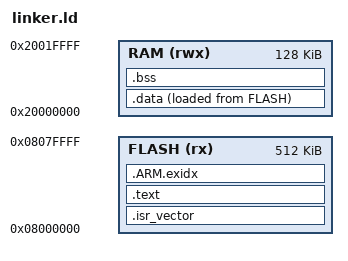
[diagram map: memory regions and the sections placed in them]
ENTRY(Reset_Handler)

MEMORY
{
    FLASH (rx)  : ORIGIN = 0x08000000, LENGTH = 512K
    RAM   (rwx) : ORIGIN = 0x20000000, LENGTH = 128K
}

_estack = ORIGIN(RAM) + LENGTH(RAM);
_stack_size = 4K;

SECTIONS
{
    .isr_vector :
    {
        . = ALIGN(4);
        KEEP(*(.isr_vector))
        . = ALIGN(4);
    } > FLASH

    .text :
    {
        . = ALIGN(4);
        *(.text*)
        *(.rodata*)
        KEEP(*(.init))
        KEEP(*(.fini))
        . = ALIGN(4);
        _etext = .;
    } > FLASH

    .ARM.exidx :
    {
        *(.ARM.exidx*)
    } > FLASH

    _sidata = LOADADDR(.data);

    .data :
    {
        . = ALIGN(4);
        _sdata = .;
        *(.data*)
        . = ALIGN(4);
        _edata = .;
    } > RAM AT > FLASH

    .bss (NOLOAD) :
    {
        . = ALIGN(4);
        _sbss = .;
        *(.bss*)
        *(COMMON)
        . = ALIGN(4);
        _ebss = .;
    } > RAM

    . = ALIGN(8);
    _end = .;

    ASSERT(_end + _stack_size <= _estack, "RAM overflow: static data leaves less than 4K stack")
}
